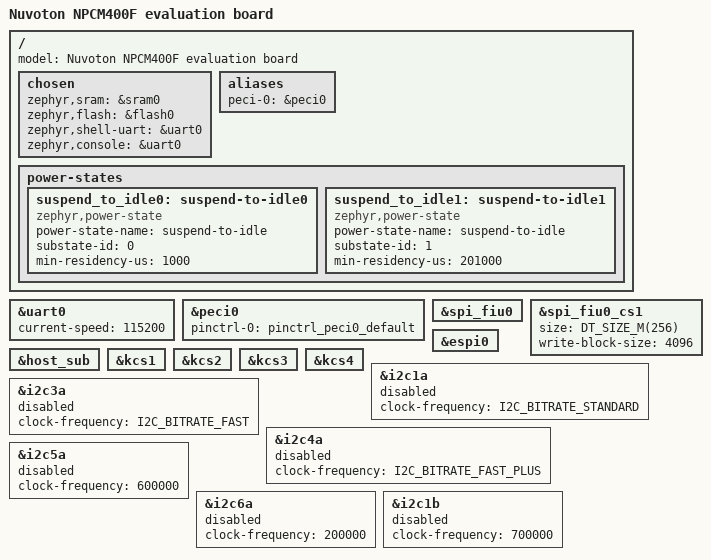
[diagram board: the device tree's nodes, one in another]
/*
 * Copyright (c) 2021 Nuvoton Technology Corporation.
 *
 * SPDX-License-Identifier: Apache-2.0
 */

/dts-v1/;

#include <nuvoton/npcm400fm4.dtsi>
#include <dt-bindings/i2c/i2c.h>

/ {
	model = "Nuvoton NPCM400F evaluation board";

	chosen {
		zephyr,sram = &sram0;
		zephyr,flash = &flash0;
		zephyr,shell-uart = &uart0;
		zephyr,console = &uart0;
	};

	aliases {
		peci-0 = &peci0;
	};


	power-states {
		suspend_to_idle0: suspend-to-idle0 {
			compatible = "zephyr,power-state";
			power-state-name = "suspend-to-idle";
			substate-id = <0>;
			min-residency-us = <1000>;
		};

		suspend_to_idle1: suspend-to-idle1 {
			compatible = "zephyr,power-state";
			power-state-name = "suspend-to-idle";
			substate-id = <1>;
			min-residency-us = <201000>;
		};
	};
};

&uart0 {
	status = "okay";
	current-speed = <115200>;
};

&peci0 {
	status = "okay";
	pinctrl-0 = <&pinctrl_peci0_default>;
};

&spi_fiu0 {
	status = "okay";
};

&spi_fiu0_cs1 {
	/* 256 => 32M */
	size = <DT_SIZE_M(256)>;
	write-block-size = <4096>;
	status = "okay";
};

&espi0 {
	status = "okay";
};

&host_sub {
	status = "okay";
};

&kcs1 {
	status = "okay";
};

&kcs2 {
	status = "okay";
};

&kcs3 {
	status = "okay";
};

&kcs4 {
	status = "okay";
};

/*
 * I2C supported bitrate:
 *   I2C_BITRATE_STANDARD: 100 Kbit/s
 *   I2C_BITRATE_FAST: 400 Kbit/s
 *   I2C_BITRATE_FAST_PLUS: 1 Mbit/s
 *   number: 100000, 200000, ... , 900000, 1000000
 */
&i2c1a {
	clock-frequency = <I2C_BITRATE_STANDARD>;
	status = "disabled";
};

&i2c3a {
	clock-frequency = <I2C_BITRATE_FAST>;
	status = "disabled";
};

&i2c4a {
	clock-frequency = <I2C_BITRATE_FAST_PLUS>;
	status = "disabled";
};

&i2c5a {
	clock-frequency = <600000>;
	status = "disabled";
};

&i2c6a {
	clock-frequency = <200000>;
	status = "disabled";
};

&i2c1b {
	clock-frequency = <700000>;
	status = "disabled";
};
